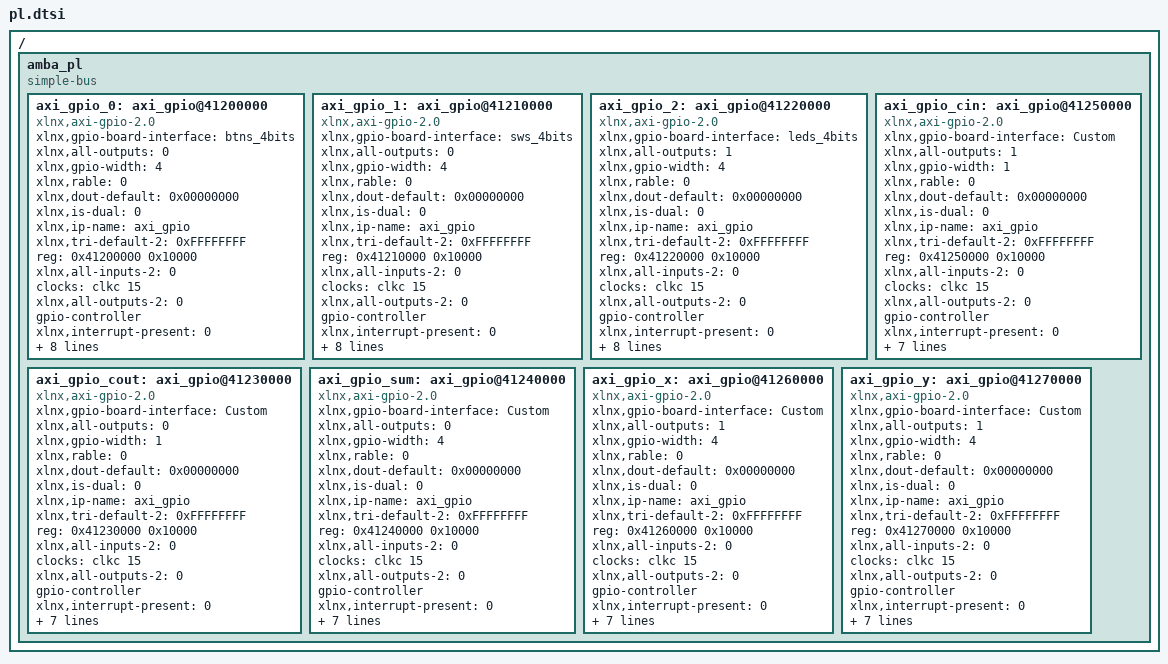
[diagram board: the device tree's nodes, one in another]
/ {
	amba_pl: amba_pl {
		ranges;
		compatible = "simple-bus";
		#address-cells = <1>;
		#size-cells = <1>;
		axi_gpio_0: axi_gpio@41200000 {
			xlnx,gpio-board-interface = "btns_4bits";
			compatible = "xlnx,axi-gpio-2.0" , "xlnx,xps-gpio-1.00.a";
			xlnx,all-outputs = <0>;
			#gpio-cells = <2>;
			xlnx,gpio-width = <4>;
			xlnx,rable = <0>;
			xlnx,dout-default = <0x00000000>;
			xlnx,is-dual = <0>;
			xlnx,ip-name = "axi_gpio";
			xlnx,tri-default-2 = <0xFFFFFFFF>;
			reg = <0x41200000 0x10000>;
			xlnx,all-inputs-2 = <0>;
			clocks = <&clkc 15>;
			xlnx,all-outputs-2 = <0>;
			gpio-controller;
			xlnx,interrupt-present = <0>;
			xlnx,gpio2-board-interface = "Custom";
			xlnx,edk-iptype = "PERIPHERAL";
			xlnx,dout-default-2 = <0x00000000>;
			xlnx,gpio2-width = <32>;
			status = "okay";
			clock-names = "s_axi_aclk";
			xlnx,use-board-flow;
			xlnx,tri-default = <0xFFFFFFFF>;
			xlnx,name = "axi_gpio_0";
			xlnx,all-inputs = <1>;
		};
		axi_gpio_1: axi_gpio@41210000 {
			xlnx,gpio-board-interface = "sws_4bits";
			compatible = "xlnx,axi-gpio-2.0" , "xlnx,xps-gpio-1.00.a";
			xlnx,all-outputs = <0>;
			#gpio-cells = <2>;
			xlnx,gpio-width = <4>;
			xlnx,rable = <0>;
			xlnx,dout-default = <0x00000000>;
			xlnx,is-dual = <0>;
			xlnx,ip-name = "axi_gpio";
			xlnx,tri-default-2 = <0xFFFFFFFF>;
			reg = <0x41210000 0x10000>;
			xlnx,all-inputs-2 = <0>;
			clocks = <&clkc 15>;
			xlnx,all-outputs-2 = <0>;
			gpio-controller;
			xlnx,interrupt-present = <0>;
			xlnx,gpio2-board-interface = "Custom";
			xlnx,edk-iptype = "PERIPHERAL";
			xlnx,dout-default-2 = <0x00000000>;
			xlnx,gpio2-width = <32>;
			status = "okay";
			clock-names = "s_axi_aclk";
			xlnx,use-board-flow;
			xlnx,tri-default = <0xFFFFFFFF>;
			xlnx,name = "axi_gpio_1";
			xlnx,all-inputs = <1>;
		};
		axi_gpio_2: axi_gpio@41220000 {
			xlnx,gpio-board-interface = "leds_4bits";
			compatible = "xlnx,axi-gpio-2.0" , "xlnx,xps-gpio-1.00.a";
			xlnx,all-outputs = <1>;
			#gpio-cells = <2>;
			xlnx,gpio-width = <4>;
			xlnx,rable = <0>;
			xlnx,dout-default = <0x00000000>;
			xlnx,is-dual = <0>;
			xlnx,ip-name = "axi_gpio";
			xlnx,tri-default-2 = <0xFFFFFFFF>;
			reg = <0x41220000 0x10000>;
			xlnx,all-inputs-2 = <0>;
			clocks = <&clkc 15>;
			xlnx,all-outputs-2 = <0>;
			gpio-controller;
			xlnx,interrupt-present = <0>;
			xlnx,gpio2-board-interface = "Custom";
			xlnx,edk-iptype = "PERIPHERAL";
			xlnx,dout-default-2 = <0x00000000>;
			xlnx,gpio2-width = <32>;
			status = "okay";
			clock-names = "s_axi_aclk";
			xlnx,use-board-flow;
			xlnx,tri-default = <0xFFFFFFFF>;
			xlnx,name = "axi_gpio_2";
			xlnx,all-inputs = <0>;
		};
		axi_gpio_cin: axi_gpio@41250000 {
			xlnx,gpio-board-interface = "Custom";
			compatible = "xlnx,axi-gpio-2.0" , "xlnx,xps-gpio-1.00.a";
			xlnx,all-outputs = <1>;
			#gpio-cells = <2>;
			xlnx,gpio-width = <1>;
			xlnx,rable = <0>;
			xlnx,dout-default = <0x00000000>;
			xlnx,is-dual = <0>;
			xlnx,ip-name = "axi_gpio";
			xlnx,tri-default-2 = <0xFFFFFFFF>;
			reg = <0x41250000 0x10000>;
			xlnx,all-inputs-2 = <0>;
			clocks = <&clkc 15>;
			xlnx,all-outputs-2 = <0>;
			gpio-controller;
			xlnx,interrupt-present = <0>;
			xlnx,gpio2-board-interface = "Custom";
			xlnx,edk-iptype = "PERIPHERAL";
			xlnx,dout-default-2 = <0x00000000>;
			xlnx,gpio2-width = <32>;
			status = "okay";
			clock-names = "s_axi_aclk";
			xlnx,tri-default = <0xFFFFFFFF>;
			xlnx,name = "axi_gpio_cin";
			xlnx,all-inputs = <0>;
		};
		axi_gpio_cout: axi_gpio@41230000 {
			xlnx,gpio-board-interface = "Custom";
			compatible = "xlnx,axi-gpio-2.0" , "xlnx,xps-gpio-1.00.a";
			xlnx,all-outputs = <0>;
			#gpio-cells = <2>;
			xlnx,gpio-width = <1>;
			xlnx,rable = <0>;
			xlnx,dout-default = <0x00000000>;
			xlnx,is-dual = <0>;
			xlnx,ip-name = "axi_gpio";
			xlnx,tri-default-2 = <0xFFFFFFFF>;
			reg = <0x41230000 0x10000>;
			xlnx,all-inputs-2 = <0>;
			clocks = <&clkc 15>;
			xlnx,all-outputs-2 = <0>;
			gpio-controller;
			xlnx,interrupt-present = <0>;
			xlnx,gpio2-board-interface = "Custom";
			xlnx,edk-iptype = "PERIPHERAL";
			xlnx,dout-default-2 = <0x00000000>;
			xlnx,gpio2-width = <32>;
			status = "okay";
			clock-names = "s_axi_aclk";
			xlnx,tri-default = <0xFFFFFFFF>;
			xlnx,name = "axi_gpio_cout";
			xlnx,all-inputs = <1>;
		};
		axi_gpio_sum: axi_gpio@41240000 {
			xlnx,gpio-board-interface = "Custom";
			compatible = "xlnx,axi-gpio-2.0" , "xlnx,xps-gpio-1.00.a";
			xlnx,all-outputs = <0>;
			#gpio-cells = <2>;
			xlnx,gpio-width = <4>;
			xlnx,rable = <0>;
			xlnx,dout-default = <0x00000000>;
			xlnx,is-dual = <0>;
			xlnx,ip-name = "axi_gpio";
			xlnx,tri-default-2 = <0xFFFFFFFF>;
			reg = <0x41240000 0x10000>;
			xlnx,all-inputs-2 = <0>;
			clocks = <&clkc 15>;
			xlnx,all-outputs-2 = <0>;
			gpio-controller;
			xlnx,interrupt-present = <0>;
			xlnx,gpio2-board-interface = "Custom";
			xlnx,edk-iptype = "PERIPHERAL";
			xlnx,dout-default-2 = <0x00000000>;
			xlnx,gpio2-width = <32>;
			status = "okay";
			clock-names = "s_axi_aclk";
			xlnx,tri-default = <0xFFFFFFFF>;
			xlnx,name = "axi_gpio_sum";
			xlnx,all-inputs = <1>;
		};
		axi_gpio_x: axi_gpio@41260000 {
			xlnx,gpio-board-interface = "Custom";
			compatible = "xlnx,axi-gpio-2.0" , "xlnx,xps-gpio-1.00.a";
			xlnx,all-outputs = <1>;
			#gpio-cells = <2>;
			xlnx,gpio-width = <4>;
			xlnx,rable = <0>;
			xlnx,dout-default = <0x00000000>;
			xlnx,is-dual = <0>;
			xlnx,ip-name = "axi_gpio";
			xlnx,tri-default-2 = <0xFFFFFFFF>;
			reg = <0x41260000 0x10000>;
			xlnx,all-inputs-2 = <0>;
			clocks = <&clkc 15>;
			xlnx,all-outputs-2 = <0>;
			gpio-controller;
			xlnx,interrupt-present = <0>;
			xlnx,gpio2-board-interface = "Custom";
			xlnx,edk-iptype = "PERIPHERAL";
			xlnx,dout-default-2 = <0x00000000>;
			xlnx,gpio2-width = <32>;
			status = "okay";
			clock-names = "s_axi_aclk";
			xlnx,tri-default = <0xFFFFFFFF>;
			xlnx,name = "axi_gpio_x";
			xlnx,all-inputs = <0>;
		};
		axi_gpio_y: axi_gpio@41270000 {
			xlnx,gpio-board-interface = "Custom";
			compatible = "xlnx,axi-gpio-2.0" , "xlnx,xps-gpio-1.00.a";
			xlnx,all-outputs = <1>;
			#gpio-cells = <2>;
			xlnx,gpio-width = <4>;
			xlnx,rable = <0>;
			xlnx,dout-default = <0x00000000>;
			xlnx,is-dual = <0>;
			xlnx,ip-name = "axi_gpio";
			xlnx,tri-default-2 = <0xFFFFFFFF>;
			reg = <0x41270000 0x10000>;
			xlnx,all-inputs-2 = <0>;
			clocks = <&clkc 15>;
			xlnx,all-outputs-2 = <0>;
			gpio-controller;
			xlnx,interrupt-present = <0>;
			xlnx,gpio2-board-interface = "Custom";
			xlnx,edk-iptype = "PERIPHERAL";
			xlnx,dout-default-2 = <0x00000000>;
			xlnx,gpio2-width = <32>;
			status = "okay";
			clock-names = "s_axi_aclk";
			xlnx,tri-default = <0xFFFFFFFF>;
			xlnx,name = "axi_gpio_y";
			xlnx,all-inputs = <0>;
		};
	};
};
